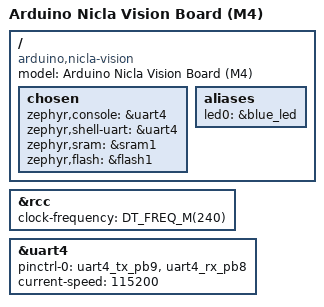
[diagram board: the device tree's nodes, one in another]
/*
 * Copyright 2024 Felipe Neves
 *
 * SPDX-License-Identifier: Apache-2.0
 */

/dts-v1/;
#include <st/h7/stm32h747Xi_m4.dtsi>
#include <st/h7/stm32h747a(g-i)ix-pinctrl.dtsi>
#include "arduino_nicla_vision.dtsi"

/ {
	compatible = "arduino,nicla-vision";
	model = "Arduino Nicla Vision Board (M4)";

	chosen {
		zephyr,console = &uart4;
		zephyr,shell-uart = &uart4;
		zephyr,sram = &sram1;
		zephyr,flash = &flash1;
	};

	aliases {
		led0 = &blue_led;
	};
};

&rcc {
	clock-frequency = <DT_FREQ_M(240)>;
};

&uart4 {
	pinctrl-0 = <&uart4_tx_pb9 &uart4_rx_pb8>;
	pinctrl-names = "default";
	current-speed = <115200>;
	status = "okay";
};
